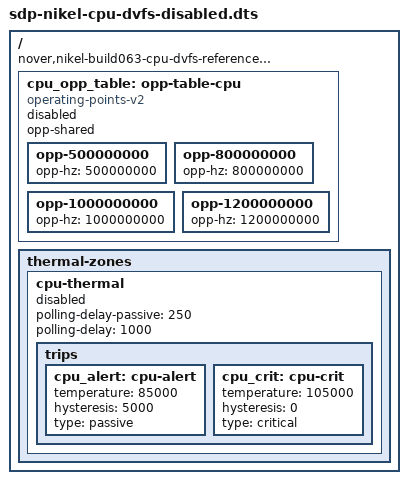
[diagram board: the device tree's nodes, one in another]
/dts-v1/;

/*
 * BUILD 063: CPU DVFS/thermal reference fixture; NOT a real board DT, NOT
 * bootable. OPP frequencies/voltages and temperature thresholds are UNVERIFIED
 * placeholders and MUST come from validated Nike-L data. cpufreq-dt consumes
 * operating-points-v2; the TMU sensor is still a Build 058 prototype. Disabled.
 */
/ {
	compatible = "nover,nikel-build063-cpu-dvfs-reference-only";
	#address-cells = <1>;
	#size-cells = <1>;

	/* TODO: placeholder OPPs - replace with hardware-validated values. */
	cpu_opp_table: opp-table-cpu {
		compatible = "operating-points-v2";
		opp-shared;
		status = "disabled";

		opp-500000000  { opp-hz = /bits/ 64 <500000000>; };
		opp-800000000  { opp-hz = /bits/ 64 <800000000>; };
		opp-1000000000 { opp-hz = /bits/ 64 <1000000000>; };
		opp-1200000000 { opp-hz = /bits/ 64 <1200000000>; };
		/* TODO: opp-microvolt per OPP once cpu-supply is known. */
	};

	thermal-zones {
		cpu-thermal {
			polling-delay-passive = <250>;
			polling-delay = <1000>;
			/* TODO: real TMU sensor phandle (Build 058 prototype). */
			status = "disabled";

			trips {
				cpu_alert: cpu-alert {
					temperature = <85000>;
					hysteresis = <5000>;
					type = "passive";
				};
				cpu_crit: cpu-crit {
					temperature = <105000>;
					hysteresis = <0>;
					type = "critical";
				};
			};
		};
	};
};
